# HSM register map
Vendor: Texas Instruments
Peripheral module from a debugger description file (folder CC27xxx20).
Registers are 32-bit, access per field, reset 0x0 unless marked. A register's access mark holds for its fields unless they carry their own. Offsets are as the file gives them; lines under a group give offsets from that group; [hi:lo] are bit positions; {n}, {i} and the like mark numbered series; 'fields as' and 'values as' point back to an identical list; <NAME> marks a mode.

## HSM — HSM is a Root of Trust Engine that protects valuable assets, such as secret keys for embedded security sensitive applications in a Trusted Execution Environment
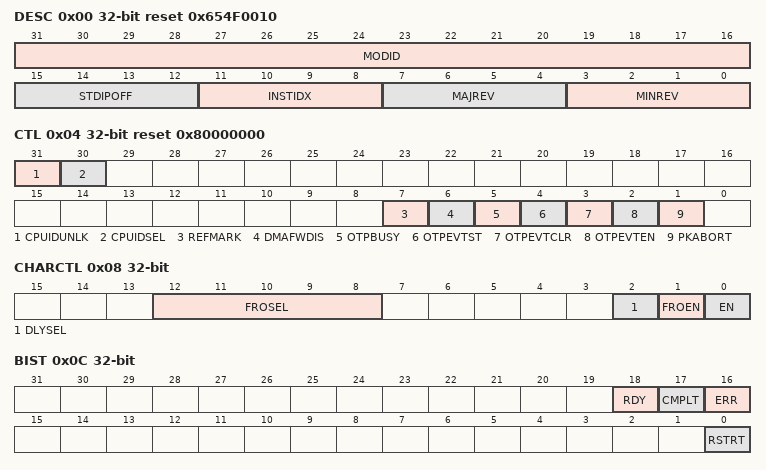
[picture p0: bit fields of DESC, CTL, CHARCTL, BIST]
0x00 DESC ro reset 0x654F0010 — Description Register. This register provides IP module ID, revision information, instance index and standard MMR registers offset.
  [31:16] MODID — Module identification contains a unique peripheral identification number.
  [15:12] STDIPOFF — Standard IP MMR block offset. Standard IP MMRs are the set of from aggregated IRQ registers till DTB. 0: Standard IP MMRs do not exist 0x1-0xF: Standard IP MMRs begin at offset of (64*STDIPOFF from the base IP address)
  [11:8] INSTIDX — IP Instance ID number. If multiple instances of IP exist in the device, this field can identify the instance number (0-15).
  [7:4] MAJREV — Major revision of IP
  [3:0] MINREV — Minor revision of IP
0x04 CTL reset 0x80000000 — Control Register
  [31] CPUIDUNLK rw — CPUID Lock. Sets sticky '0' lock for CTL.CPUIDSEL
    1=UNLOCK; 0=LOCK
  [30] CPUIDSEL rw — CPUID Select. Selects between ROMFW CPUID and Application CPUID
    1=ROMID (Assert); 0=APPID (Dassert)
  [7] REFMARK rw — Refresher Marker. Trigger writting refresh marker. This bit is auto cleared when programming is done
    1=TRG (Trigger/Busy); 0=DONE
  [6] DMAFWDIS rw — DMA Firewall Disable
    1=DIS (DMA Firewall Disabled); 0=EN (DMA Firewall Enabled)
  [5] OTPBUSY ro — OTP Busy. OTP contoller is busy
  [4] OTPEVTST ro — OTP Event Status.
    1=START (OTP Start); 0=DONE (OTP Done)
  [3] OTPEVTCLR wo — OTP Event Clear
    1=CLR (Request PKA Abort)
  [2] OTPEVTEN rw — OTP Event Enable
    1=EN (OTP Event Enable); 0=DIS (OTP Event Disable)
  [1] PKABORT wo — PKA Abort. Writing 1 to this bit requests PKA Abort, writing 0 has no effect
    1=REQ (Request PKA Abort)
0x08 CHARCTL — Characterization Controls for FRO
  [12:8] FROSEL rw — Selects FRO to characterize
  [2] DLYSEL rw — Selects delay in target FRO.This input must only be changed when CHARCTL.FROEN = 0
    1=TAP95 (Selects a tap on the approx. 95% of full length); 0=FULL (Selects the full chain length)
  [1] FROEN rw — Enables selected FRO
    1=EN (Enabled); 0=DIS (Disabled)
  [0] EN rw — Enables` characterization
    1=EN (Enabled); 0=DIS (Disabled)
0x0C BIST — BIST Controls and Status for CRNG
  [18] RDY ro — CRNG BIST ready. When 1, BIST and health checks are complete
  [17] CMPLT ro — CRNG BIST Complete. When 1, BIST checks are done
  [16] ERR ro — CRNG BIST Error. When 1, BIST failed
  [0] RSTRT rw — CRNG BIST Restart. When 1, starts BIST sequence. Ignored when BIST.RDY = 0
